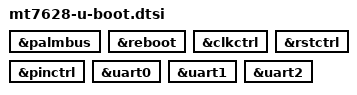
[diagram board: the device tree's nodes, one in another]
// SPDX-License-Identifier: GPL-2.0
/*
 * Copyright (C) 2020 MediaTek Inc.
 *
 * Author: Weijie Gao <weijie.gao@mediatek.com>
 */

&palmbus {
	u-boot,dm-all;
};

&reboot {
	u-boot,dm-all;
};

&clkctrl {
	u-boot,dm-all;
};

&rstctrl {
	u-boot,dm-all;
};

&pinctrl {
	u-boot,dm-all;
};

&uart0 {
	u-boot,dm-all;
};

&uart1 {
	u-boot,dm-all;
};

&uart2 {
	u-boot,dm-all;
};
